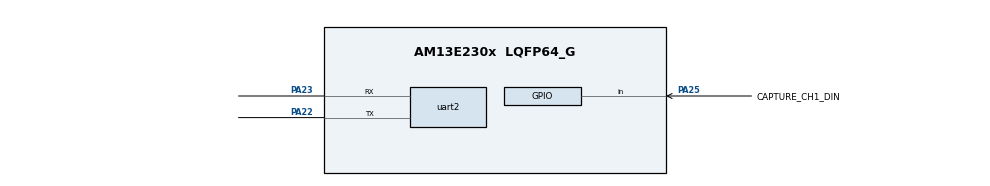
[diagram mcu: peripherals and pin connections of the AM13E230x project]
/**
 *
 * @cliArgs --device "AM13E230x" --part "AM13E230x" --package "LQFP64_G" --product "AM13E2X SDK@26.01.00"
 * @versions {"tool":"1.28.0+4696"}
 */

/**
 * Import the modules used in this configuration.
 */
const adc        = scripting.addModule("/drivers/adc", {}, false);
const adc1       = adc.addInstance();
const dma        = scripting.addModule("/drivers/dma");
const dma1       = dma.addInstance();
const ecap       = scripting.addModule("/drivers/ecap", {}, false);
const ecap1      = ecap.addInstance();
const ecap2      = ecap.addInstance();
const gpio       = scripting.addModule("/drivers/gpio");
const gpio1      = gpio.addInstance();
const inputxbar  = scripting.addModule("/drivers/inputxbar", {}, false);
const inputxbar1 = inputxbar.addInstance();
const inputxbar2 = inputxbar.addInstance();
const mcpwm      = scripting.addModule("/drivers/mcpwm", {}, false);
const mcpwm1     = mcpwm.addInstance();
const mcpwm2     = mcpwm.addInstance();
const mcpwm3     = mcpwm.addInstance();
const mcpwm4     = mcpwm.addInstance();
const mcpwm5     = mcpwm.addInstance();
const sysctl     = scripting.addModule("/drivers/sysctl");
const systick    = scripting.addModule("/drivers/systick");
const uart       = scripting.addModule("/drivers/uart", {}, false);
const uart1      = uart.addInstance();
const uart2      = uart.addInstance();

/**
 * Write custom configuration values to the imported modules.
 */
adc1.$name                   = "HSADC";
adc1.enableSEQs              = true;
adc1.interruptPulseMode      = "DL_ADC_PULSE_END_OF_CONV";
adc1.enabledDMAInts          = ["DMAINT1"];
adc1.numberOfSOCs            = 2;
adc1.numberOfSEQs            = 1;
adc1.DMAINT1.enableInterrupt = true;
adc1.DMAINT1.continuousMode  = true;
adc1.DMAINT1.SOCSource       = "SOC1";
adc1.SOC0.channel            = "PA16";
adc1.SOC1.channel            = "PA17";
adc1.SEQ1.name               = "SEQ0";
adc1.SEQ1.triggerSel         = "DL_ADC_TRIGGER_PWM1_SOCA";
adc1.SEQ1.numberOfSOCs       = 2;

dma.registerIntDMA0 = true;

dma1.$name                 = "HSADC_DMA";
dma1.triggerSelect         = "DL_DMA_TRIGGER_SOURCE_ADC0_DMA_TRIG1";
dma1.addressMode           = "f2b";
dma1.configureTransferSize = true;
dma1.transferSize          = 8192;
dma1.transferMode          = "FULL_CH_REPEAT_SINGLE";
dma1.enableInterrupt       = true;

ecap1.$name                  = "CAPTURE_ECAP0";
ecap1.interruptSourceCapture = ["DL_ECAP_ISR_SOURCE_CEVT3"];
ecap1.eventStop              = "DL_ECAP_EVENT_3";
ecap1.event2Polarity         = "DL_ECAP_EVENT_FALLING_EDGE";
ecap1.event4Polarity         = "DL_ECAP_EVENT_FALLING_EDGE";
ecap1.registerInterrupt      = true;

ecap2.$name                  = "CAPTURE_ECAP1";
ecap2.ecapBase               = "ECAP1";
ecap2.ecapInput              = "DL_ECAP_INPUT_INPUTXBAR2";
ecap2.eventStop              = "DL_ECAP_EVENT_3";
ecap2.event2Polarity         = "DL_ECAP_EVENT_FALLING_EDGE";
ecap2.event4Polarity         = "DL_ECAP_EVENT_FALLING_EDGE";
ecap2.interruptSourceCapture = ["DL_ECAP_ISR_SOURCE_CEVT3"];

gpio1.$name                         = "CAPTURE_DIN_GPIO_GROUP";
gpio1.port                          = "PORTA";
gpio1.associatedPins.create(2);
gpio1.associatedPins[0].$name       = "CAPTURE_CH0_DIN";
gpio1.associatedPins[0].direction   = "INPUT";
gpio1.associatedPins[0].assignedPin = "2";
gpio1.associatedPins[1].$name       = "CAPTURE_CH1_DIN";
gpio1.associatedPins[1].direction   = "INPUT";
gpio1.associatedPins[1].assignedPin = "25";
gpio1.associatedPins[1].pin.$assign = "PA25";

inputxbar1.$name         = "CAPTURE_INPUTXBAR1";
inputxbar1.inputxbarGpio = "GPIO02_PA2";

inputxbar2.$name          = "CAPTURE_INPUTXBAR2";
inputxbar2.inputxbarInput = "DL_XBAR_INPUT2";
inputxbar2.inputxbarGpio  = "GPIO25_PA25";

mcpwm1.$name                                     = "PWM_CH0";
mcpwm1.mcpwmBase                                 = "MCPWM0";
mcpwm1.pinList                                   = ["1A"];
mcpwm1.enablePWM2A                               = false;
mcpwm1.enablePWM1B                               = false;
mcpwm1.enablePWM2B                               = false;
mcpwm1.enablePWM3A                               = false;
mcpwm1.enablePWM3B                               = false;
mcpwm1.timeBase.$name                            = "drivers_mcpwm_v0_mcpwm_timeBase0";
mcpwm1.timeBase.counterMode                      = "DL_MCPWM_COUNTER_MODE_UP";
mcpwm1.timeBase.emulationMode                    = "DL_MCPWM_EMULATION_FREE_RUN";
mcpwm1.timeBase.periodValue                      = 10000;
mcpwm1.counterCompare.$name                      = "drivers_mcpwm_v0_mcpwm_counterCompare0";
mcpwm1.counterCompare.PWM1_CMPA                  = 1000;
mcpwm1.actionQualifier.$name                     = "drivers_mcpwm_v0_mcpwm_actionQualifier0";
mcpwm1.actionQualifier.PWM1A.$name               = "drivers_mcpwm_v0_mcpwm_actionQualifierEvents0";
mcpwm1.actionQualifier.PWM1A.actionAtZero        = "DL_MCPWM_AQ_OUTPUT_HIGH";
mcpwm1.actionQualifier.PWM1A.actionAtCountUpCmpA = "DL_MCPWM_AQ_OUTPUT_LOW";
mcpwm1.loadMode.$name                            = "drivers_mcpwm_v0_mcpwm_loadMode0";
mcpwm1.peripheral["1A"].$assign                  = "PB3";

mcpwm2.$name                                     = "PWM_CH1";
mcpwm2.mcpwmBase                                 = "MCPWM4";
mcpwm2.pinList                                   = ["1B"];
mcpwm2.enablePWM1A                               = false;
mcpwm2.enablePWM2A                               = false;
mcpwm2.enablePWM3A                               = false;
mcpwm2.enablePWM2B                               = false;
mcpwm2.enablePWM3B                               = false;
mcpwm2.timeBase.$name                            = "drivers_mcpwm_v0_mcpwm_timeBase1";
mcpwm2.timeBase.counterMode                      = "DL_MCPWM_COUNTER_MODE_UP";
mcpwm2.timeBase.emulationMode                    = "DL_MCPWM_EMULATION_FREE_RUN";
mcpwm2.counterCompare.$name                      = "drivers_mcpwm_v0_mcpwm_counterCompare1";
mcpwm2.actionQualifier.$name                     = "drivers_mcpwm_v0_mcpwm_actionQualifier1";
mcpwm2.actionQualifier.PWM1B.$name               = "drivers_mcpwm_v0_mcpwm_actionQualifierEvents2";
mcpwm2.actionQualifier.PWM1B.actionAtZero        = "DL_MCPWM_AQ_OUTPUT_HIGH";
mcpwm2.actionQualifier.PWM1B.actionAtCountUpCmpB = "DL_MCPWM_AQ_OUTPUT_LOW";
mcpwm2.loadMode.$name                            = "drivers_mcpwm_v0_mcpwm_loadMode1";
mcpwm2.peripheral.$assign                        = "MCPWM4";
mcpwm2.peripheral["1B"].$assign                  = "PA7";

mcpwm3.$name                                     = "PWM_CH2";
mcpwm3.mcpwmBase                                 = "MCPWM3";
mcpwm3.pinList                                   = ["3A"];
mcpwm3.enablePWM1A                               = false;
mcpwm3.enablePWM1B                               = false;
mcpwm3.enablePWM2A                               = false;
mcpwm3.enablePWM2B                               = false;
mcpwm3.enablePWM3B                               = false;
mcpwm3.timeBase.$name                            = "drivers_mcpwm_v0_mcpwm_timeBase2";
mcpwm3.timeBase.counterMode                      = "DL_MCPWM_COUNTER_MODE_UP";
mcpwm3.timeBase.emulationMode                    = "DL_MCPWM_EMULATION_FREE_RUN";
mcpwm3.counterCompare.$name                      = "drivers_mcpwm_v0_mcpwm_counterCompare2";
mcpwm3.actionQualifier.$name                     = "drivers_mcpwm_v0_mcpwm_actionQualifier2";
mcpwm3.actionQualifier.PWM3A.$name               = "drivers_mcpwm_v0_mcpwm_actionQualifierEvents6";
mcpwm3.actionQualifier.PWM3A.actionAtZero        = "DL_MCPWM_AQ_OUTPUT_HIGH";
mcpwm3.actionQualifier.PWM3A.actionAtCountUpCmpA = "DL_MCPWM_AQ_OUTPUT_LOW";
mcpwm3.loadMode.$name                            = "drivers_mcpwm_v0_mcpwm_loadMode2";
mcpwm3.peripheral["3A"].$assign                  = "PB1";

mcpwm4.$name                                     = "PWM_CH3";
mcpwm4.mcpwmBase                                 = "MCPWM2";
mcpwm4.pinList                                   = ["2A"];
mcpwm4.enablePWM1B                               = false;
mcpwm4.enablePWM1A                               = false;
mcpwm4.enablePWM2B                               = false;
mcpwm4.enablePWM3A                               = false;
mcpwm4.enablePWM3B                               = false;
mcpwm4.timeBase.$name                            = "drivers_mcpwm_v0_mcpwm_timeBase3";
mcpwm4.timeBase.counterMode                      = "DL_MCPWM_COUNTER_MODE_UP";
mcpwm4.timeBase.emulationMode                    = "DL_MCPWM_EMULATION_FREE_RUN";
mcpwm4.counterCompare.$name                      = "drivers_mcpwm_v0_mcpwm_counterCompare3";
mcpwm4.actionQualifier.$name                     = "drivers_mcpwm_v0_mcpwm_actionQualifier3";
mcpwm4.actionQualifier.PWM2A.$name               = "drivers_mcpwm_v0_mcpwm_actionQualifierEvents4";
mcpwm4.actionQualifier.PWM2A.actionAtZero        = "DL_MCPWM_AQ_OUTPUT_HIGH";
mcpwm4.actionQualifier.PWM2A.actionAtCountUpCmpA = "DL_MCPWM_AQ_OUTPUT_LOW";
mcpwm4.loadMode.$name                            = "drivers_mcpwm_v0_mcpwm_loadMode3";
mcpwm4.peripheral["2A"].$assign                  = "PB2";

mcpwm5.$name                                     = "HSADC_TRIGGER_PWM";
mcpwm5.mcpwmBase                                 = "MCPWM1";
mcpwm5.pinList                                   = ["1A"];
mcpwm5.enablePWM1B                               = false;
mcpwm5.enablePWM2A                               = false;
mcpwm5.enablePWM2B                               = false;
mcpwm5.enablePWM3A                               = false;
mcpwm5.enablePWM3B                               = false;
mcpwm5.enableEventTrigger                        = true;
mcpwm5.timeBase.$name                            = "drivers_mcpwm_v0_mcpwm_timeBase4";
mcpwm5.timeBase.counterMode                      = "DL_MCPWM_COUNTER_MODE_UP";
mcpwm5.timeBase.periodValue                      = 9999;
mcpwm5.timeBase.emulationMode                    = "DL_MCPWM_EMULATION_FREE_RUN";
mcpwm5.counterCompare.$name                      = "drivers_mcpwm_v0_mcpwm_counterCompare4";
mcpwm5.actionQualifier.$name                     = "drivers_mcpwm_v0_mcpwm_actionQualifier4";
mcpwm5.actionQualifier.PWM1A.$name               = "drivers_mcpwm_v0_mcpwm_actionQualifierEvents1";
mcpwm5.actionQualifier.PWM1A.actionAtZero        = "DL_MCPWM_AQ_OUTPUT_HIGH";
mcpwm5.actionQualifier.PWM1A.actionAtCountUpCmpA = "DL_MCPWM_AQ_OUTPUT_LOW";
mcpwm5.loadMode.$name                            = "drivers_mcpwm_v0_mcpwm_loadMode4";
mcpwm5.eventTrigger.$name                        = "drivers_mcpwm_v0_mcpwm_eventTrigger0";
mcpwm5.eventTrigger.SOCA_enable                  = true;
mcpwm5.eventTrigger.SOCA_eventSource             = "DL_MCPWM_SOC_TBCTR_ZERO";

sysctl.useHFCLK     = true;
sysctl.SYSPLLSource = "DL_SYSCTL_SYSPLL_REF_HFCLK";
sysctl.SYSPLL_Qdiv  = 32;
sysctl.VREFSource   = "DL_SYSCTL_VREF_INTERNAL_3_3_V";

systick.periodEnable    = true;
systick.period          = 16777216;
systick.interruptEnable = true;
systick.registerInt     = true;

uart1.$name                            = "RS485_UART";
uart1.targetBaudRate                   = 115200;
uart1.enabledInterrupts                = ["DL_UART_INTERRUPT_FRAMING_ERROR","DL_UART_INTERRUPT_OVERRUN_ERROR","DL_UART_INTERRUPT_PARITY_ERROR","DL_UART_INTERRUPT_RX"];
uart1.registerInterrupt                = true;
uart1.peripheral.$assign               = "UC4";
uart1.txPinConfig.$name                = "drivers_gpio_v0_gpioPinConfig0";
uart1.txPinConfig.direction            = scripting.forceWrite("OUTPUT");
uart1.txPinConfig.hideOutputInversion  = scripting.forceWrite(false);
uart1.txPinConfig.onlyInternalResistor = scripting.forceWrite(false);
uart1.txPinConfig.passedPeripheralType = scripting.forceWrite("Digital");
uart1.rxPinConfig.$name                = "drivers_gpio_v0_gpioPinConfig1";
uart1.rxPinConfig.hideOutputInversion  = scripting.forceWrite(false);
uart1.rxPinConfig.onlyInternalResistor = scripting.forceWrite(false);
uart1.rxPinConfig.passedPeripheralType = scripting.forceWrite("Digital");

uart2.$name                            = "USER_UART";
uart2.targetBaudRate                   = 115200;
uart2.registerInterrupt                = true;
uart2.enabledInterrupts                = ["DL_UART_INTERRUPT_FRAMING_ERROR","DL_UART_INTERRUPT_OVERRUN_ERROR","DL_UART_INTERRUPT_PARITY_ERROR","DL_UART_INTERRUPT_RX"];
uart2.peripheral.$assign               = "UC2";
uart2.peripheral.rxPin.$assign         = "PA23";
uart2.peripheral.txPin.$assign         = "PA22";
uart2.txPinConfig.$name                = "drivers_gpio_v0_gpioPinConfig2";
uart2.txPinConfig.direction            = scripting.forceWrite("OUTPUT");
uart2.txPinConfig.hideOutputInversion  = scripting.forceWrite(false);
uart2.txPinConfig.onlyInternalResistor = scripting.forceWrite(false);
uart2.txPinConfig.passedPeripheralType = scripting.forceWrite("Digital");
uart2.rxPinConfig.$name                = "drivers_gpio_v0_gpioPinConfig3";
uart2.rxPinConfig.hideOutputInversion  = scripting.forceWrite(false);
uart2.rxPinConfig.onlyInternalResistor = scripting.forceWrite(false);
uart2.rxPinConfig.passedPeripheralType = scripting.forceWrite("Digital");

/**
 * Pinmux solution for unlocked pins/peripherals. This ensures that minor changes to the automatic solver in a future
 * version of the tool will not impact the pinmux you originally saw.  These lines can be completely deleted in order to
 * re-solve from scratch.
 */
adc1.SOC0.peripheral.$suggestSolution        = "ANALOG";
adc1.SOC0.peripheral.AIN16.$suggestSolution  = "PA16";
adc1.SOC1.peripheral.$suggestSolution        = "ANALOG";
adc1.SOC1.peripheral.AIN17.$suggestSolution  = "PA17";
gpio1.associatedPins[0].pin.$suggestSolution = "PA2";
mcpwm1.peripheral.$suggestSolution           = "MCPWM0";
mcpwm3.peripheral.$suggestSolution           = "MCPWM3";
mcpwm4.peripheral.$suggestSolution           = "MCPWM2";
mcpwm5.peripheral.$suggestSolution           = "MCPWM1";
mcpwm5.peripheral["1A"].$suggestSolution     = "PA15";
sysctl.peripheral.$suggestSolution           = "SYSCTL";
sysctl.peripheral.x1Pin.$suggestSolution     = "PC16_X1";
sysctl.peripheral.x2Pin.$suggestSolution     = "PC17_X2";
uart1.peripheral.rxPin.$suggestSolution      = "PA1";
uart1.peripheral.txPin.$suggestSolution      = "PA0";
